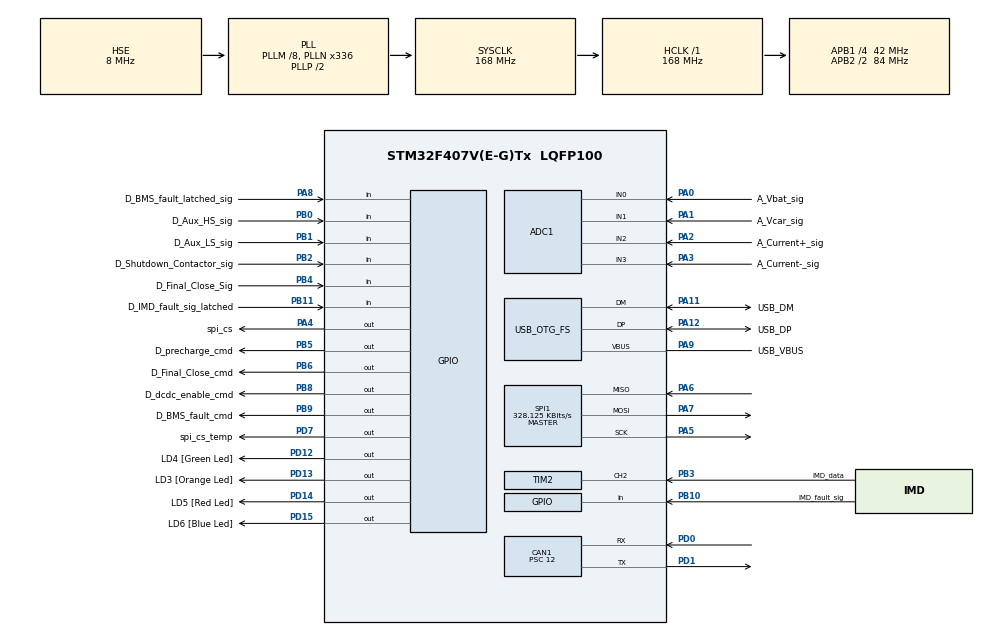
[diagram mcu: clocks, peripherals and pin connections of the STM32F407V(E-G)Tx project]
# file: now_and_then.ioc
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ADC1.Channel-0\#ChannelRegularConversion=ADC_CHANNEL_0
ADC1.Channel-1\#ChannelRegularConversion=ADC_CHANNEL_1
ADC1.Channel-2\#ChannelRegularConversion=ADC_CHANNEL_2
ADC1.Channel-3\#ChannelRegularConversion=ADC_CHANNEL_3
ADC1.ClockPrescaler=ADC_CLOCK_SYNC_PCLK_DIV4
ADC1.ContinuousConvMode=DISABLE
ADC1.DMAContinuousRequests=DISABLE
ADC1.EOCSelection=ADC_EOC_SEQ_CONV
ADC1.NbrOfConversion=4
ADC1.NbrOfConversionFlag=1
ADC1.Rank-0\#ChannelRegularConversion=1
ADC1.Rank-1\#ChannelRegularConversion=2
ADC1.Rank-2\#ChannelRegularConversion=3
ADC1.Rank-3\#ChannelRegularConversion=4
ADC1.SamplingTime-0\#ChannelRegularConversion=ADC_SAMPLETIME_15CYCLES
ADC1.SamplingTime-1\#ChannelRegularConversion=ADC_SAMPLETIME_15CYCLES
ADC1.SamplingTime-2\#ChannelRegularConversion=ADC_SAMPLETIME_15CYCLES
ADC1.SamplingTime-3\#ChannelRegularConversion=ADC_SAMPLETIME_15CYCLES
ADC1.ScanConvMode=ENABLE
ADC1.master=1
CAN1.AWUM=ENABLE
CAN1.BS1=CAN_BS1_11TQ
CAN1.BS2=CAN_BS2_2TQ
CAN1.CalculateBaudRate=250000
CAN1.CalculateTimeBit=3999.99
CAN1.CalculateTimeQuantum=285.7142857142857
CAN1.Prescaler=12
CAN1.SJW=CAN_SJW_4TQ
CAN1.TXFP=ENABLE
Dma.ADC1.0.Direction=DMA_PERIPH_TO_MEMORY
Dma.ADC1.0.FIFOMode=DMA_FIFOMODE_DISABLE
Dma.ADC1.0.Instance=DMA2_Stream0
Dma.ADC1.0.MemDataAlignment=DMA_MDATAALIGN_WORD
Dma.ADC1.0.MemInc=DMA_MINC_ENABLE
Dma.ADC1.0.Mode=DMA_NORMAL
Dma.ADC1.0.PeriphDataAlignment=DMA_PDATAALIGN_WORD
Dma.ADC1.0.PeriphInc=DMA_PINC_DISABLE
Dma.ADC1.0.Priority=DMA_PRIORITY_LOW
Dma.Request0=ADC1
FREERTOS.Tasks01=defaultTask,24,128,StartDefaultTask,Default,NULL,Dynamic,NULL,NULL;task_ltc,8,128,start_task_ltc,As external,NULL,Dynamic,NULL,NULL;task_main,24,256,start_task_main,As external,NULL,Dynamic,NULL,NULL;task_can_bus,40,128,start_task_can_bus,As external,NULL,Dynamic,NULL,NULL;task_adc,24,128,start_task_adc,As external,NULL,Dynamic,NULL,NULL
FREERTOS.configLIBRARY_MAX_SYSCALL_INTERRUPT_PRIORITY=5
FREERTOS.configTICK_RATE_HZ=100
Mcu.Family=STM32F4
Mcu.Name=STM32F407V(E-G)Tx
Mcu.Package=LQFP100
NVIC.ADC_IRQn=true\:5\:0\:false\:false\:true\:true\:true\:true
NVIC.CAN1_RX0_IRQn=true\:5\:0\:true\:false\:true\:true\:true\:true
NVIC.CAN1_RX1_IRQn=true\:5\:0\:true\:false\:true\:true\:true\:true
NVIC.CAN1_SCE_IRQn=true\:5\:0\:true\:false\:true\:true\:true\:true
NVIC.CAN1_TX_IRQn=true\:5\:0\:true\:false\:true\:true\:true\:true
NVIC.DMA2_Stream0_IRQn=true\:5\:0\:false\:false\:true\:true\:false\:true
NVIC.OTG_FS_IRQn=true\:5\:0\:false\:false\:true\:true\:true\:true
NVIC.PriorityGroup=NVIC_PRIORITYGROUP_4
NVIC.TIM2_IRQn=true\:5\:0\:false\:false\:true\:true\:true\:true
NVIC.TIM6_DAC_IRQn=true\:0\:0\:false\:false\:true\:false\:false\:true
NVIC.TimeBase=TIM6_DAC_IRQn
NVIC.TimeBaseIP=TIM6
PA0-WKUP.GPIO_Label=A_Vbat_sig
PA0-WKUP.Signal=ADCx_IN0
PA1.GPIO_Label=A_Vcar_sig
PA1.Signal=ADCx_IN1
PA11.GPIO_Label=USB_DM
PA11.Mode=Device_Only
PA11.Signal=USB_OTG_FS_DM
PA12.GPIO_Label=USB_DP
PA12.Mode=Device_Only
PA12.Signal=USB_OTG_FS_DP
PA13.GPIO_Label=sw_dio
PA13.Mode=Serial_Wire
PA13.Signal=SYS_JTMS-SWDIO
PA14.GPIO_Label=sw_clk
PA14.Mode=Serial_Wire
PA14.Signal=SYS_JTCK-SWCLK
PA2.GPIO_Label=A_Current+_sig
PA2.Signal=ADCx_IN2
PA3.GPIO_Label=A_Current-_sig
PA3.Signal=ADCx_IN3
PA4.GPIO_Label=spi_cs
PA4.GPIO_PuPd=GPIO_PULLUP
PA4.Signal=GPIO_Output
PA5.Mode=Full_Duplex_Master
PA5.Signal=SPI1_SCK
PA6.GPIO_PuPd=GPIO_PULLUP
PA6.GPIO_Speed=GPIO_SPEED_FREQ_VERY_HIGH
PA6.Mode=Full_Duplex_Master
PA6.Signal=SPI1_MISO
PA7.Mode=Full_Duplex_Master
PA7.Signal=SPI1_MOSI
PA8.GPIO_Label=D_BMS_fault_latched_sig
PA8.GPIO_PuPd=GPIO_NOPULL
PA8.Signal=GPIO_Input
PA9.GPIO_Label=USB_VBUS
PA9.Mode=Activate_VBUS
PA9.Signal=USB_OTG_FS_VBUS
PB0.GPIO_Label=D_Aux_HS_sig
PB0.GPIO_PuPd=GPIO_PULLUP
PB0.Signal=GPIO_Input
PB1.GPIO_Label=D_Aux_LS_sig
PB1.GPIO_PuPd=GPIO_PULLUP
PB1.Signal=GPIO_Input
PB10.GPIO_Label=IMD_fault_sig
PB10.Signal=GPIO_Input
PB11.GPIO_Label=D_IMD_fault_sig_latched
PB11.Signal=GPIO_Input
PB2.GPIO_Label=D_Shutdown_Contactor_sig
PB2.GPIO_PuPd=GPIO_PULLUP
PB2.Signal=GPIO_Input
PB3.GPIO_Label=IMD_data
PB3.GPIO_PuPd=GPIO_NOPULL
PB3.GPIO_Speed=GPIO_SPEED_FREQ_HIGH
PB3.Signal=S_TIM2_CH2
PB4.GPIO_Label=D_Final_Close_Sig
PB4.GPIO_PuPd=GPIO_PULLUP
PB4.Signal=GPIO_Input
PB5.GPIO_Label=D_precharge_cmd
PB5.Signal=GPIO_Output
PB6.GPIO_Label=D_Final_Close_cmd
PB6.Signal=GPIO_Output
PB8.GPIO_Label=D_dcdc_enable_cmd
PB8.Signal=GPIO_Output
PB9.GPIO_Label=D_BMS_fault_cmd
PB9.Signal=GPIO_Output
PD0.Mode=CAN_Activate
PD0.Signal=CAN1_RX
PD1.Mode=CAN_Activate
PD1.Signal=CAN1_TX
PD12.GPIO_Label=LD4 [Green Led]
PD12.Signal=GPIO_Output
PD13.GPIO_Label=LD3 [Orange Led]
PD13.Signal=GPIO_Output
PD14.GPIO_Label=LD5 [Red Led]
PD14.Signal=GPIO_Output
PD15.GPIO_Label=LD6 [Blue Led]
PD15.Signal=GPIO_Output
PD7.GPIO_Label=spi_cs_temp
PD7.GPIO_PuPd=GPIO_PULLUP
PD7.Signal=GPIO_Output
PH0-OSC_IN.Mode=HSE-External-Oscillator
PH0-OSC_IN.Signal=RCC_OSC_IN
PH1-OSC_OUT.Mode=HSE-External-Oscillator
PH1-OSC_OUT.Signal=RCC_OSC_OUT
ProjectManager.HeapSize=0x200
ProjectManager.StackSize=0x400
ProjectManager.TargetToolchain=SW4STM32
RCC.48MHZClocksFreq_Value=48000000
RCC.AHBFreq_Value=168000000
RCC.APB1CLKDivider=RCC_HCLK_DIV4
RCC.APB1Freq_Value=42000000
RCC.APB1TimFreq_Value=84000000
RCC.APB2CLKDivider=RCC_HCLK_DIV2
RCC.APB2Freq_Value=84000000
RCC.APB2TimFreq_Value=168000000
RCC.CortexFreq_Value=168000000
RCC.HCLKFreq_Value=168000000
RCC.HSE_VALUE=8000000
RCC.HSI_VALUE=16000000
RCC.LSE_VALUE=32768
RCC.PLLM=8
RCC.PLLN=336
RCC.PLLQ=7
RCC.SYSCLKFreq_VALUE=168000000
RCC.SYSCLKSource=RCC_SYSCLKSOURCE_PLLCLK
RCC.VCOOutputFreq_Value=336000000
SH.ADCx_IN0.0=ADC1_IN0,IN0
SH.ADCx_IN1.0=ADC1_IN1,IN1
SH.ADCx_IN2.0=ADC1_IN2,IN2
SH.ADCx_IN3.0=ADC1_IN3,IN3
SH.S_TIM2_CH2.0=TIM2_CH2,Input_Capture2_from_TI2
SH.S_TIM2_CH2.1=TIM2_CH2,Input_Capture1_from_TI2
SH.S_TIM2_CH2.2=TIM2_CH2,TriggerSource_TI2FP2
SPI1.BaudRatePrescaler=SPI_BAUDRATEPRESCALER_256
SPI1.CLKPhase=SPI_PHASE_2EDGE
SPI1.CLKPolarity=SPI_POLARITY_HIGH
SPI1.CalculateBaudRate=328.125 KBits/s
SPI1.Direction=SPI_DIRECTION_2LINES
SPI1.FirstBit=SPI_FIRSTBIT_MSB
SPI1.Mode=SPI_MODE_MASTER
SPI1.VirtualType=VM_MASTER
TIM2.Channel-Input_Capture1_from_TI2=TIM_CHANNEL_1
TIM2.Channel-Input_Capture2_from_TI2=TIM_CHANNEL_2
TIM2.ICPolarity_CH1=TIM_INPUTCHANNELPOLARITY_FALLING
TIM2.Period=0xffffffff
USB_DEVICE.CLASS_NAME_FS=CDC
USB_DEVICE.MANUFACTURER_STRING-CDC_FS=kenovation
USB_DEVICE.PID_CDC_FS=42069
USB_DEVICE.VirtualMode-CDC_FS=Cdc
USB_DEVICE.VirtualModeFS=Cdc_FS
USB_OTG_FS.VirtualMode=Device_Only
VP_FREERTOS_VS_CMSIS_V2.Mode=CMSIS_V2
VP_SYS_VS_tim6.Mode=TIM6
VP_TIM2_VS_ControllerModeReset.Mode=Reset Mode
VP_USB_DEVICE_VS_USB_DEVICE_CDC_FS.Mode=CDC_FS
board=custom

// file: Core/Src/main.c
/* USER CODE BEGIN Header */
/**
  ******************************************************************************
  * @file           : main.c
  * @brief          : Main program body
  ******************************************************************************
  * @attention
  *
  * <h2><center>&copy; Copyright (c) 2021 STMicroelectronics.
  * All rights reserved.</center></h2>
  *
  * This software component is licensed by ST under Ultimate Liberty license
  * SLA0044, the "License"; You may not use this file except in compliance with
  * the License. You may obtain a copy of the License at:
  *                             www.st.com/SLA0044
  *
  ******************************************************************************
  */
/* USER CODE END Header */
#include <task/task_ltc.h>
#include "main.h"
#include "cmsis_os.h"
#include "adc.h"
#include "can.h"
#include "dma.h"
#include "spi.h"
#include "tim.h"
#include "usb_device.h"
#include "gpio.h"

/* USER CODE BEGIN Includes */
#include "task/task_imd_timer.h"
#include "task/task_can_bus.h"
/* USER CODE END Includes */

void SystemClock_Config(void);
void MX_FREERTOS_Init(void);

int main(void)
{

  /* MCU Configuration--------------------------------------------------------*/

  /* Reset of all peripherals, Initializes the Flash interface and the Systick. */
  HAL_Init();

  /* Configure the system clock */
  SystemClock_Config();

  /* Initialize all configured peripherals */
  MX_GPIO_Init();
  MX_DMA_Init();
  MX_CAN1_Init();
  MX_SPI1_Init();
  MX_ADC1_Init();
  MX_TIM2_Init();
  /* USER CODE BEGIN 2 */
    create_IMD_queue();
    TIM2_start_capture();
    setup_can_bus_task();
    task_ltc_setup();
  /* USER CODE END 2 */

  /* Init scheduler */
  osKernelInitialize();  /* Call init function for freertos objects (in freertos.c) */
  MX_FREERTOS_Init();
  /* Start scheduler */
  osKernelStart();

  /* We should never get here as control is now taken by the scheduler */
  /* Infinite loop */
    while (1) {

    }
}

void SystemClock_Config(void)
{
  RCC_OscInitTypeDef RCC_OscInitStruct = {0};
  RCC_ClkInitTypeDef RCC_ClkInitStruct = {0};

  /** Configure the main internal regulator output voltage
  */
  __HAL_RCC_PWR_CLK_ENABLE();
  __HAL_PWR_VOLTAGESCALING_CONFIG(PWR_REGULATOR_VOLTAGE_SCALE1);
  /** Initializes the RCC Oscillators according to the specified parameters
  * in the RCC_OscInitTypeDef structure.
  */
  RCC_OscInitStruct.OscillatorType = RCC_OSCILLATORTYPE_HSE;
  RCC_OscInitStruct.HSEState = RCC_HSE_ON;
  RCC_OscInitStruct.PLL.PLLState = RCC_PLL_ON;
  RCC_OscInitStruct.PLL.PLLSource = RCC_PLLSOURCE_HSE;
  RCC_OscInitStruct.PLL.PLLM = 8;
  RCC_OscInitStruct.PLL.PLLN = 336;
  RCC_OscInitStruct.PLL.PLLP = RCC_PLLP_DIV2;
  RCC_OscInitStruct.PLL.PLLQ = 7;
  if (HAL_RCC_OscConfig(&RCC_OscInitStruct) != HAL_OK)
  {
    Error_Handler();
  }
  /** Initializes the CPU, AHB and APB buses clocks
  */
  RCC_ClkInitStruct.ClockType = RCC_CLOCKTYPE_HCLK|RCC_CLOCKTYPE_SYSCLK
                              |RCC_CLOCKTYPE_PCLK1|RCC_CLOCKTYPE_PCLK2;
  RCC_ClkInitStruct.SYSCLKSource = RCC_SYSCLKSOURCE_PLLCLK;
  RCC_ClkInitStruct.AHBCLKDivider = RCC_SYSCLK_DIV1;
  RCC_ClkInitStruct.APB1CLKDivider = RCC_HCLK_DIV4;
  RCC_ClkInitStruct.APB2CLKDivider = RCC_HCLK_DIV2;

  if (HAL_RCC_ClockConfig(&RCC_ClkInitStruct, FLASH_LATENCY_5) != HAL_OK)
  {
    Error_Handler();
  }
}

 /**
  * @brief  Period elapsed callback in non blocking mode
  * @note   This function is called  when TIM6 interrupt took place, inside
  * HAL_TIM_IRQHandler(). It makes a direct call to HAL_IncTick() to increment
  * a global variable "uwTick" used as application time base.
  * @param  htim : TIM handle
  * @retval None
  */
void HAL_TIM_PeriodElapsedCallback(TIM_HandleTypeDef *htim)
{
  if (htim->Instance == TIM6) {
    HAL_IncTick();
  }
}

void Error_Handler(void)
{
}

/************************ (C) COPYRIGHT STMicroelectronics *****END OF FILE****/

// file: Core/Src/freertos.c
/* USER CODE BEGIN Header */
/**
  ******************************************************************************
  * File Name          : freertos.c
  * Description        : Code for freertos applications
  ******************************************************************************
  * @attention
  *
  * <h2><center>&copy; Copyright (c) 2021 STMicroelectronics.
  * All rights reserved.</center></h2>
  *
  * This software component is licensed by ST under Ultimate Liberty license
  * SLA0044, the "License"; You may not use this file except in compliance with
  * the License. You may obtain a copy of the License at:
  *                             www.st.com/SLA0044
  *
  ******************************************************************************
  */
/* USER CODE END Header */

#include "FreeRTOS.h"
#include "task.h"
#include "main.h"
#include "cmsis_os.h"

/* Definitions for defaultTask */
osThreadId_t defaultTaskHandle;
const osThreadAttr_t defaultTask_attributes = {
  .name = "defaultTask",
  .stack_size = 128 * 4,
  .priority = (osPriority_t) osPriorityNormal,
};
/* Definitions for task_ltc */
osThreadId_t task_ltcHandle;
const osThreadAttr_t task_ltc_attributes = {
  .name = "task_ltc",
  .stack_size = 128 * 4,
  .priority = (osPriority_t) osPriorityLow,
};
/* Definitions for task_main */
osThreadId_t task_mainHandle;
const osThreadAttr_t task_main_attributes = {
  .name = "task_main",
  .stack_size = 256 * 4,
  .priority = (osPriority_t) osPriorityNormal,
};
/* Definitions for task_can_bus */
osThreadId_t task_can_busHandle;
const osThreadAttr_t task_can_bus_attributes = {
  .name = "task_can_bus",
  .stack_size = 128 * 4,
  .priority = (osPriority_t) osPriorityHigh,
};
/* Definitions for task_adc */
osThreadId_t task_adcHandle;
const osThreadAttr_t task_adc_attributes = {
  .name = "task_adc",
  .stack_size = 128 * 4,
  .priority = (osPriority_t) osPriorityNormal,
};

void StartDefaultTask(void *argument);

[[noreturn]]

extern void start_task_ltc(void *argument);
extern void start_task_main(void *argument);

[[noreturn]]

extern void start_task_can_bus(void *argument);
extern void start_task_adc(void *argument);

extern void MX_USB_DEVICE_Init(void);
void MX_FREERTOS_Init(void); /* (MISRA C 2004 rule 8.1) */

void MX_FREERTOS_Init(void) {

  /* Create the thread(s) */
  /* creation of defaultTask */
  defaultTaskHandle = osThreadNew(StartDefaultTask, NULL, &defaultTask_attributes);

  /* creation of task_ltc */
  task_ltcHandle = osThreadNew(start_task_ltc, NULL, &task_ltc_attributes);

  /* creation of task_main */
  task_mainHandle = osThreadNew(start_task_main, NULL, &task_main_attributes);

  /* creation of task_can_bus */
  task_can_busHandle = osThreadNew(start_task_can_bus, NULL, &task_can_bus_attributes);

  /* creation of task_adc */
  task_adcHandle = osThreadNew(start_task_adc, NULL, &task_adc_attributes);

}

void StartDefaultTask(void *argument)
{
  /* init code for USB_DEVICE */
  MX_USB_DEVICE_Init();
  /* USER CODE BEGIN StartDefaultTask */
  /* Infinite loop */
  for(;;)
  {
    osDelay(UINT32_MAX);
  }
  /* USER CODE END StartDefaultTask */
}

/************************ (C) COPYRIGHT STMicroelectronics *****END OF FILE****/
